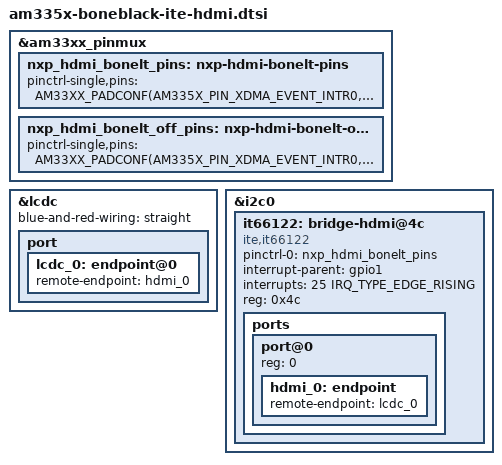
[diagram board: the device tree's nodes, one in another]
// SPDX-License-Identifier: GPL-2.0-only
/*
 * Copyright (C) 2012 Texas Instruments Incorporated - https://www.ti.com/
 */

#include <dt-bindings/display/tda998x.h>
#include <dt-bindings/interrupt-controller/irq.h>

&am33xx_pinmux {
	nxp_hdmi_bonelt_pins: nxp-hdmi-bonelt-pins {
		pinctrl-single,pins = <
			AM33XX_PADCONF(AM335X_PIN_XDMA_EVENT_INTR0, PIN_OUTPUT_PULLDOWN, MUX_MODE3)
			AM33XX_PADCONF(AM335X_PIN_LCD_DATA0, PIN_OUTPUT, MUX_MODE0)
			AM33XX_PADCONF(AM335X_PIN_LCD_DATA1, PIN_OUTPUT, MUX_MODE0)
			AM33XX_PADCONF(AM335X_PIN_LCD_DATA2, PIN_OUTPUT, MUX_MODE0)
			AM33XX_PADCONF(AM335X_PIN_LCD_DATA3, PIN_OUTPUT, MUX_MODE0)
			AM33XX_PADCONF(AM335X_PIN_LCD_DATA4, PIN_OUTPUT, MUX_MODE0)
			AM33XX_PADCONF(AM335X_PIN_LCD_DATA5, PIN_OUTPUT, MUX_MODE0)
			AM33XX_PADCONF(AM335X_PIN_LCD_DATA6, PIN_OUTPUT, MUX_MODE0)
			AM33XX_PADCONF(AM335X_PIN_LCD_DATA7, PIN_OUTPUT, MUX_MODE0)
			AM33XX_PADCONF(AM335X_PIN_LCD_DATA8, PIN_OUTPUT, MUX_MODE0)
			AM33XX_PADCONF(AM335X_PIN_LCD_DATA9, PIN_OUTPUT, MUX_MODE0)
			AM33XX_PADCONF(AM335X_PIN_LCD_DATA10, PIN_OUTPUT, MUX_MODE0)
			AM33XX_PADCONF(AM335X_PIN_LCD_DATA11, PIN_OUTPUT, MUX_MODE0)
			AM33XX_PADCONF(AM335X_PIN_LCD_DATA12, PIN_OUTPUT, MUX_MODE0)
			AM33XX_PADCONF(AM335X_PIN_LCD_DATA13, PIN_OUTPUT, MUX_MODE0)
			AM33XX_PADCONF(AM335X_PIN_LCD_DATA14, PIN_OUTPUT, MUX_MODE0)
			AM33XX_PADCONF(AM335X_PIN_LCD_DATA15, PIN_OUTPUT, MUX_MODE0)
			AM33XX_PADCONF(AM335X_PIN_LCD_VSYNC, PIN_OUTPUT_PULLDOWN, MUX_MODE0)
			AM33XX_PADCONF(AM335X_PIN_LCD_HSYNC, PIN_OUTPUT_PULLDOWN, MUX_MODE0)
			AM33XX_PADCONF(AM335X_PIN_LCD_PCLK, PIN_OUTPUT_PULLDOWN, MUX_MODE0)
			AM33XX_PADCONF(AM335X_PIN_LCD_AC_BIAS_EN, PIN_OUTPUT_PULLDOWN, MUX_MODE0)
		>;
	};

	nxp_hdmi_bonelt_off_pins: nxp-hdmi-bonelt-off-pins {
		pinctrl-single,pins = <
			AM33XX_PADCONF(AM335X_PIN_XDMA_EVENT_INTR0, PIN_OUTPUT_PULLDOWN, MUX_MODE3)
		>;
	};

	//mcasp0_pins: mcasp0-pins {
	//	pinctrl-single,pins = <
	//		AM33XX_PADCONF(AM335X_PIN_MCASP0_AHCLKX, PIN_INPUT_PULLUP, MUX_MODE0) /* mcasp0_ahcklx.mcasp0_ahclkx */
	//		AM33XX_PADCONF(AM335X_PIN_MCASP0_AHCLKR, PIN_OUTPUT_PULLDOWN, MUX_MODE2) /* mcasp0_ahclkr.mcasp0_axr2*/
	//		AM33XX_PADCONF(AM335X_PIN_MCASP0_FSX, PIN_OUTPUT_PULLUP, MUX_MODE0)
	//		AM33XX_PADCONF(AM335X_PIN_MCASP0_ACLKX, PIN_OUTPUT_PULLDOWN, MUX_MODE0)
	//		AM33XX_PADCONF(AM335X_PIN_GPMC_A11, PIN_OUTPUT_PULLDOWN, MUX_MODE7) /* gpmc_a11.GPIO1_27 */
	//	>;
	//};
};

&lcdc {
	status = "okay";

	/* If you want to get 24 bit RGB and 16 BGR mode instead of
	 * current 16 bit RGB and 24 BGR modes, set the propety
	 * below to "crossed" and uncomment the video-ports -property
	 * in tda19988 node.
	 */
	blue-and-red-wiring = "straight";

	port {
		lcdc_0: endpoint@0 {
			remote-endpoint = <&hdmi_0>;
		};
	};
};

&i2c0 {
	it66122: bridge-hdmi@4c {
		compatible = "ite,it66122";
		pinctrl-names = "default";
		pinctrl-0 = <&nxp_hdmi_bonelt_pins>;

		//nxp,calib-gpios = <&gpio1 25 0>;
		//interrupts-extended = <&gpio1 25 IRQ_TYPE_LEVEL_LOW>;

		//vcn33-supply = <&mt6358_vcn33_wifi_reg>;
		//vcn18-supply = <&mt6358_vcn18_reg>;
		//vrf12-supply = <&mt6358_vrf12_reg>;
		//reset-gpios = <&pio 160 GPIO_ACTIVE_LOW>;
		interrupt-parent = <&gpio1>;
		interrupts = <25 IRQ_TYPE_EDGE_RISING>;
		reg = <0x4c>;

		/* Convert 24bit BGR to RGB, e.g. cross red and blue wiring */
		/* video-ports = <0x234501>; */

		ports {
			#address-cells = <1>;
			#size-cells = <0>;

			port@0 {
				reg = <0>;

				hdmi_0: endpoint {
					remote-endpoint = <&lcdc_0>;
				};
			};
		};
	};
};
